# AT32F421xx register map
Vendor: Keil; Series: AT32F421; File version: 1.0
CPU: CM4 r0p1, little endian, no MPU, FPU, 4 interrupt priority bits
Registers are 32-bit, read-write, reset 0x0 unless marked. A register's access mark holds for its fields unless they carry their own. Offsets are from the block's base; [hi:lo] are bit positions; lines under a group give offsets from that group; {n}, {i} and the like mark numbered series.

## USART1 — Universal synchronous asynchronous receiver transmitter
Base 0x40013800
Same registers: USART2 0x40004400
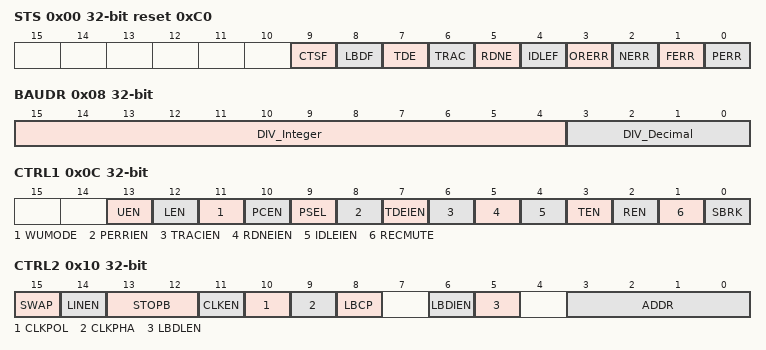
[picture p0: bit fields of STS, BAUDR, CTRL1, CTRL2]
0x00 STS reset 0xC0 — Status register
  [9] CTSF — CTS flag
  [8] LBDF — LIN break detection flag
  [7] TDE ro — Transmit data register empty
  [6] TRAC — Transmission complete
  [5] RDNE — Read data register not empty
  [4] IDLEF ro — IDLE line detected
  [3] ORERR ro — Overrun error
  [2] NERR ro — Noise error flag
  [1] FERR ro — Framing error
  [0] PERR ro — Parity error
0x04 DT — Data register
  [8:0] DT — Data value
0x08 BAUDR — Baud rate register
  [15:4] DIV_Integer — mantissa of USARTDIV
  [3:0] DIV_Decimal — fraction of USARTDIV
0x0C CTRL1 — Control register 1
  [13] UEN — USART enable
  [12] LEN — Word length
  [11] WUMODE — Wakeup method
  [10] PCEN — Parity control enable
  [9] PSEL — Parity selection
  [8] PERRIEN — PE interrupt enable
  [7] TDEIEN — TXE interrupt enable
  [6] TRACIEN — Transmission complete interrupt enable
  [5] RDNEIEN — RXNE interrupt enable
  [4] IDLEIEN — IDLE interrupt enable
  [3] TEN — Transmitter enable
  [2] REN — Receiver enable
  [1] RECMUTE — Receiver wakeup
  [0] SBRK — Send break
0x10 CTRL2 — Control register 2
  [15] SWAP — Tx Rx swap mode enable
  [14] LINEN — LIN mode enable
  [13:12] STOPB — STOP bits
  [11] CLKEN — Clock enable
  [10] CLKPOL — Clock polarity
  [9] CLKPHA — Clock phase
  [8] LBCP — Last bit clock pulse
  [6] LBDIEN — LIN break detection interrupt enable
  [5] LBDLEN — lin break detection length
  [3:0] ADDR — Address of the USART node
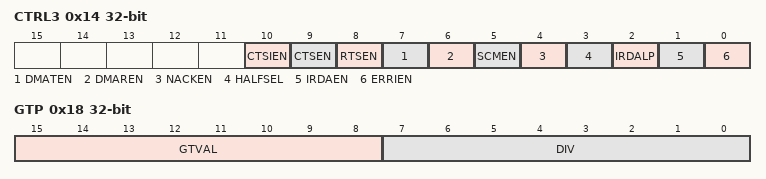
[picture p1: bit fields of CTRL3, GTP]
0x14 CTRL3 — Control register 3
  [10] CTSIEN — CTS interrupt enable
  [9] CTSEN — CTS enable
  [8] RTSEN — RTS enable
  [7] DMATEN — DMA enable transmitter
  [6] DMAREN — DMA enable receiver
  [5] SCMEN — Smartcard mode enable
  [4] NACKEN — Smartcard NACK enable
  [3] HALFSEL — Half-duplex selection
  [2] IRDALP — IrDA low-power
  [1] IRDAEN — IrDA mode enable
  [0] ERRIEN — Error interrupt enable
0x18 GTP — Guard time and prescaler register
  [15:8] GTVAL — Guard time value
  [7:0] DIV — Prescaler value

## ADC1 — Analog to digital converter
Base 0x40012400
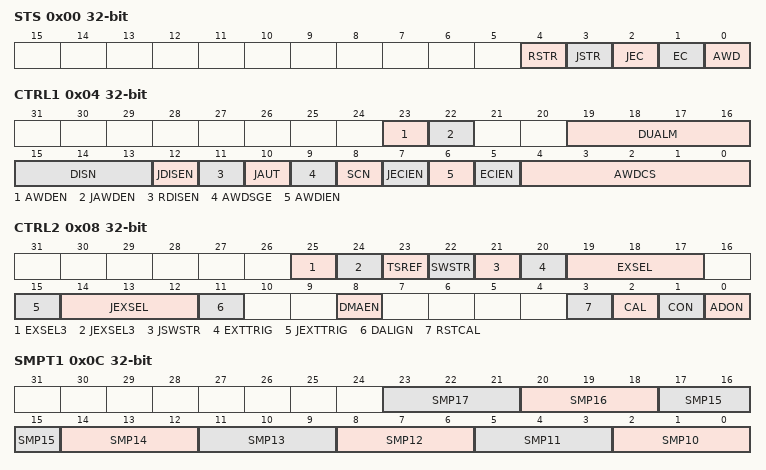
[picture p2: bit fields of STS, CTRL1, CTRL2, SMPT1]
0x00 STS — status register
  [4] RSTR — Regular channel start flag
  [3] JSTR — Injected channel start flag
  [2] JEC — Injected channel end of conversion
  [1] EC — Regular channel end of conversion
  [0] AWD — Analog watchdog flag
0x04 CTRL1 — control register 1
  [23] AWDEN — Analog watchdog enable on regular channels
  [22] JAWDEN — Analog watchdog enable on injected channels
  [19:16] DUALM — Dual mode selection
  [15:13] DISN — Discontinuous mode channel count
  [12] JDISEN — Discontinuous mode on injected channels
  [11] RDISEN — Discontinuous mode on regular channels
  [10] JAUT — Automatic injected group conversion
  [9] AWDSGE — Enable the watchdog on a single channel in scan mode
  [8] SCN — Scan mode
  [7] JECIEN — Interrupt enable for injected channels
  [6] AWDIEN — Analog watchdog interrupt enable
  [5] ECIEN — Interrupt enable for EOC
  [4:0] AWDCS — Analog watchdog channel select bits
0x08 CTRL2 — control register 2
  [25] EXSEL3 — External event select for regular group
  [24] JEXSEL3 — External event select for injected group
  [23] TSREF — Temperature sensor and VREFINT enable
  [22] SWSTR — Start conversion of regular channels
  [21] JSWSTR — Start conversion of injected channels
  [20] EXTTRIG — External trigger conversion mode for regular channels
  [19:17] EXSEL — External event select for regular group
  [15] JEXTTRIG — External trigger conversion mode for injected channels
  [14:12] JEXSEL — External event select for injected group
  [11] DALIGN — Data alignment
  [8] DMAEN — Direct memory access mode
  [3] RSTCAL — Reset calibration
  [2] CAL — A/D calibration
  [1] CON — Continuous conversion
  [0] ADON — A/D converter ON / OFF
0x0C SMPT1 — sample time register 1
  [3n-28:3n-30] SMP{n} (n=10..17) — Channel {n} sample time selection
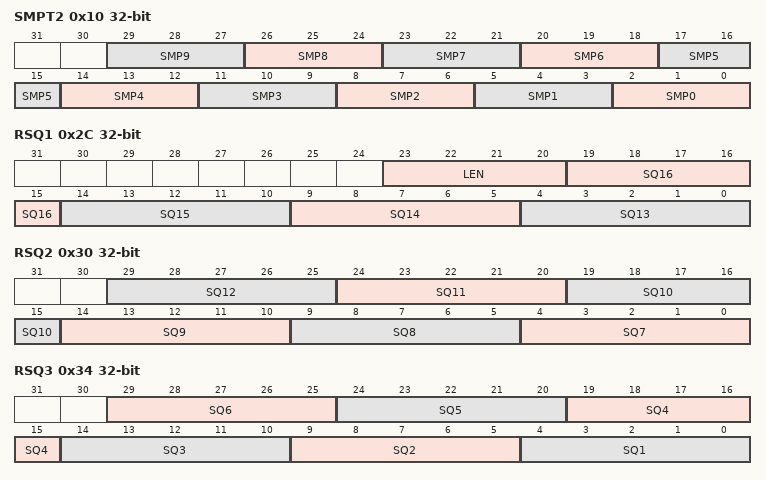
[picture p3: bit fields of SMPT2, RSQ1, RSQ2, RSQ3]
0x10 SMPT2 — sample time register 2
  [3n+2:3n] SMP{n} (n=0..9) — Channel {n} sample time selection
{0x10+4i} JOFS{i} (i=1..4) — injected channel data offset register x
  [11:0] JOFST{i} — Data offset for injected channel x
0x24 WHTR reset 0xFFF — watchdog higher threshold register
  [11:0] AWHT — Analog watchdog higher threshold
0x28 WLTR — watchdog lower threshold register
  [11:0] AWLT — Analog watchdog lower threshold
0x2C RSQ1 — regular sequence register 1
  [23:20] LEN — Regular channel sequence length
  [5n-61:5n-65] SQ{n} (n=13..16) — {n}th conversion in regular sequence
0x30 RSQ2 — regular sequence register 2
  [5n-31:5n-35] SQ{n} (n=7..12) — {n}th conversion in regular sequence
0x34 RSQ3 — regular sequence register 3
  [29:25] SQ6 — 6th conversion in regular sequence
  [24:20] SQ5 — 5th conversion in regular sequence
  [19:15] SQ4 — 4th conversion in regular sequence
  [14:10] SQ3 — 3rd conversion in regular sequence
  [9:5] SQ2 — 2nd conversion in regular sequence
  [4:0] SQ1 — 1st conversion in regular sequence
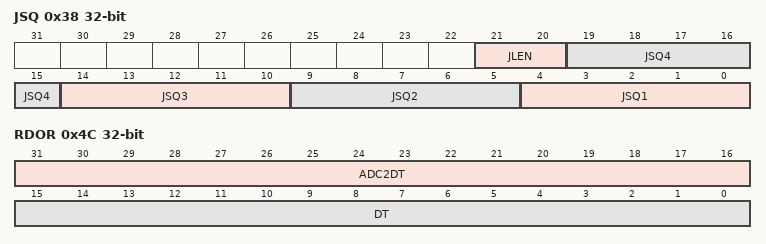
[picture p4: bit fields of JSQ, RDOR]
0x38 JSQ — injected sequence register
  [21:20] JLEN — Injected sequence length
  [19:15] JSQ4 — 4th conversion in injected sequence
  [14:10] JSQ3 — 3rd conversion in injected sequence
  [9:5] JSQ2 — 2nd conversion in injected sequence
  [4:0] JSQ1 — 1st conversion in injected sequence
{0x38+4i} JDOR{i} ro (i=1..4) — injected data register x
  [15:0] JDT — Injected data
0x4C RDOR ro — regular data register
  [31:16] ADC2DT — ADC2 data
  [15:0] DT — Regular data
